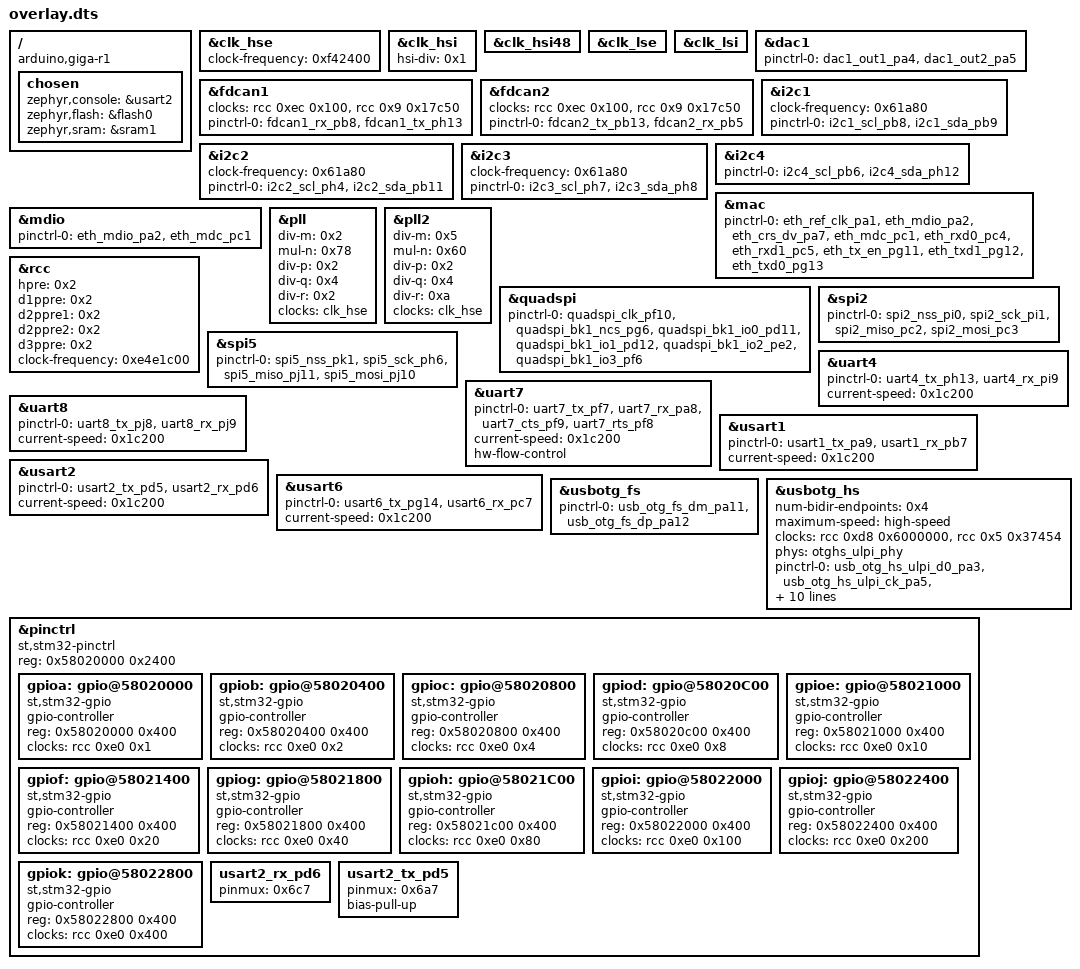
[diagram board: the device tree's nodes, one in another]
/ {
	compatible = "arduino,giga-r1";
	chosen {
		zephyr,console = &usart2;
		zephyr,flash = &flash0;
		zephyr,sram = &sram1;
	};
};
&clk_hse{
	status = "okay";
	clock-frequency = < 0xf42400 >;
};
&clk_hsi{
	status = "okay";
	hsi-div = < 0x1 >;
};
&clk_hsi48{
	status = "okay";
};
&clk_lse{
	status = "okay";
};
&clk_lsi{
	status = "okay";
};
&dac1{
	status = "okay";
	pinctrl-0 = < &dac1_out1_pa4 &dac1_out2_pa5 >;
	pinctrl-names = "default";
};
&fdcan1{
	clocks = < &rcc 0xec 0x100 >, < &rcc 0x9 0x17c50 >;
	pinctrl-0 = < &fdcan1_rx_pb8 &fdcan1_tx_ph13 >;
	pinctrl-names = "default";
};
&fdcan2{
	clocks = < &rcc 0xec 0x100 >, < &rcc 0x9 0x17c50 >;
	status = "okay";
	pinctrl-0 = < &fdcan2_tx_pb13 &fdcan2_rx_pb5 >;
	pinctrl-names = "default";
};
&i2c1{
	clock-frequency = < 0x61a80 >;
	pinctrl-0 = < &i2c1_scl_pb8 &i2c1_sda_pb9 >;
	pinctrl-names = "default";
};
&i2c2{
	clock-frequency = < 0x61a80 >;
	pinctrl-0 = < &i2c2_scl_ph4 &i2c2_sda_pb11 >;
	pinctrl-names = "default";
};
&i2c3{
	clock-frequency = < 0x61a80 >;
	pinctrl-0 = < &i2c3_scl_ph7 &i2c3_sda_ph8 >;
	pinctrl-names = "default";
};
&i2c4{
	status = "okay";
	pinctrl-0 = < &i2c4_scl_pb6 &i2c4_sda_ph12 >;
	pinctrl-names = "default";
};
&mac{
	pinctrl-0 = < &eth_ref_clk_pa1 &eth_mdio_pa2 &eth_crs_dv_pa7 &eth_mdc_pc1 &eth_rxd0_pc4 &eth_rxd1_pc5 &eth_tx_en_pg11 &eth_txd1_pg12 &eth_txd0_pg13 >;
	pinctrl-names = "default";
};
&mdio{
	status = "okay";
	pinctrl-0 = < &eth_mdio_pa2 &eth_mdc_pc1 >;
	pinctrl-names = "default";
};
&pll{
	status = "okay";
	div-m = < 0x2 >;
	mul-n = < 0x78 >;
	div-p = < 0x2 >;
	div-q = < 0x4 >;
	div-r = < 0x2 >;
	clocks = < &clk_hse >;
};
&pll2{
	status = "okay";
	div-m = < 0x5 >;
	mul-n = < 0x60 >;
	div-p = < 0x2 >;
	div-q = < 0x4 >;
	div-r = < 0xa >;
	clocks = < &clk_hse >;
};
&quadspi{
	status = "okay";
	pinctrl-0 = < &quadspi_clk_pf10 &quadspi_bk1_ncs_pg6 &quadspi_bk1_io0_pd11 &quadspi_bk1_io1_pd12 &quadspi_bk1_io2_pe2 &quadspi_bk1_io3_pf6 >;
	pinctrl-names = "default";
};
&rcc{
	hpre = < 0x2 >;
	d1ppre = < 0x2 >;
	d2ppre1 = < 0x2 >;
	d2ppre2 = < 0x2 >;
	d3ppre = < 0x2 >;
	clock-frequency = < 0xe4e1c00 >;
};
&spi2{
	pinctrl-0 = < &spi2_nss_pi0 &spi2_sck_pi1 &spi2_miso_pc2 &spi2_mosi_pc3 >;
	pinctrl-names = "default";
};
&spi5{
	status = "okay";
	pinctrl-0 = < &spi5_nss_pk1 &spi5_sck_ph6 &spi5_miso_pj11 &spi5_mosi_pj10 >;
	pinctrl-names = "default";
};
&uart4{
	pinctrl-0 = < &uart4_tx_ph13 &uart4_rx_pi9 >;
	pinctrl-names = "default";
	current-speed = < 0x1c200 >;
};
&uart7{
	status = "okay";
	pinctrl-0 = < &uart7_tx_pf7 &uart7_rx_pa8 &uart7_cts_pf9 &uart7_rts_pf8 >;
	pinctrl-names = "default";
	current-speed = < 0x1c200 >;
	hw-flow-control;
};
&uart8{
	pinctrl-0 = < &uart8_tx_pj8 &uart8_rx_pj9 >;
	pinctrl-names = "default";
	current-speed = < 0x1c200 >;
};
&usart1{
	status = "okay";
	pinctrl-0 = < &usart1_tx_pa9 &usart1_rx_pb7 >;
	pinctrl-names = "default";
	current-speed = < 0x1c200 >;
};
&usart2{
	status = "okay";
	pinctrl-0 = < &usart2_tx_pd5 &usart2_rx_pd6 >;
	pinctrl-names = "default";
	current-speed = < 0x1c200 >;
};
&usart6{
	pinctrl-0 = < &usart6_tx_pg14 &usart6_rx_pc7 >;
	pinctrl-names = "default";
	current-speed = < 0x1c200 >;
};
&usbotg_fs{
	status = "okay";
	pinctrl-0 = < &usb_otg_fs_dm_pa11 &usb_otg_fs_dp_pa12 >;
	pinctrl-names = "default";
};
&usbotg_hs{
	num-bidir-endpoints = < 0x4 >;
	maximum-speed = "high-speed";
	clocks = < &rcc 0xd8 0x6000000 >, < &rcc 0x5 0x37454 >;
	phys = < &otghs_ulpi_phy >;
	status = "okay";
	pinctrl-0 = < &usb_otg_hs_ulpi_d0_pa3 &usb_otg_hs_ulpi_ck_pa5 &usb_otg_hs_ulpi_d1_pb0 &usb_otg_hs_ulpi_d2_pb1 &usb_otg_hs_ulpi_d7_pb5 &usb_otg_hs_ulpi_d3_pb10 &usb_otg_hs_ulpi_d4_pb11 &usb_otg_hs_ulpi_d5_pb12 &usb_otg_hs_ulpi_d6_pb13 &usb_otg_hs_ulpi_stp_pc0 &usb_otg_hs_ulpi_nxt_ph4 &usb_otg_hs_ulpi_dir_pi11 >;
	pinctrl-names = "default";
};
&pinctrl{
	compatible = "st,stm32-pinctrl";
	#address-cells = < 0x1 >;
	#size-cells = < 0x1 >;
	reg = < 0x58020000 0x2400 >;
	gpioa: gpio@58020000 {
		compatible = "st,stm32-gpio";
		gpio-controller;
		#gpio-cells = < 0x2 >;
		reg = < 0x58020000 0x400 >;
		clocks = < &rcc 0xe0 0x1 >;
	};
	gpiob: gpio@58020400 {
		compatible = "st,stm32-gpio";
		gpio-controller;
		#gpio-cells = < 0x2 >;
		reg = < 0x58020400 0x400 >;
		clocks = < &rcc 0xe0 0x2 >;
	};
	gpioc: gpio@58020800 {
		compatible = "st,stm32-gpio";
		gpio-controller;
		#gpio-cells = < 0x2 >;
		reg = < 0x58020800 0x400 >;
		clocks = < &rcc 0xe0 0x4 >;
	};
	gpiod: gpio@58020C00 {
		compatible = "st,stm32-gpio";
		gpio-controller;
		#gpio-cells = < 0x2 >;
		reg = < 0x58020c00 0x400 >;
		clocks = < &rcc 0xe0 0x8 >;
	};
	gpioe: gpio@58021000 {
		compatible = "st,stm32-gpio";
		gpio-controller;
		#gpio-cells = < 0x2 >;
		reg = < 0x58021000 0x400 >;
		clocks = < &rcc 0xe0 0x10 >;
	};
	gpiof: gpio@58021400 {
		compatible = "st,stm32-gpio";
		gpio-controller;
		#gpio-cells = < 0x2 >;
		reg = < 0x58021400 0x400 >;
		clocks = < &rcc 0xe0 0x20 >;
	};
	gpiog: gpio@58021800 {
		compatible = "st,stm32-gpio";
		gpio-controller;
		#gpio-cells = < 0x2 >;
		reg = < 0x58021800 0x400 >;
		clocks = < &rcc 0xe0 0x40 >;
	};
	gpioh: gpio@58021C00 {
		compatible = "st,stm32-gpio";
		gpio-controller;
		#gpio-cells = < 0x2 >;
		reg = < 0x58021c00 0x400 >;
		clocks = < &rcc 0xe0 0x80 >;
	};
	gpioi: gpio@58022000 {
		compatible = "st,stm32-gpio";
		gpio-controller;
		#gpio-cells = < 0x2 >;
		reg = < 0x58022000 0x400 >;
		clocks = < &rcc 0xe0 0x100 >;
	};
	gpioj: gpio@58022400 {
		compatible = "st,stm32-gpio";
		gpio-controller;
		#gpio-cells = < 0x2 >;
		reg = < 0x58022400 0x400 >;
		clocks = < &rcc 0xe0 0x200 >;
	};
	gpiok: gpio@58022800 {
		compatible = "st,stm32-gpio";
		gpio-controller;
		#gpio-cells = < 0x2 >;
		reg = < 0x58022800 0x400 >;
		clocks = < &rcc 0xe0 0x400 >;
	};
	usart2_rx_pd6: usart2_rx_pd6 {
		pinmux = < 0x6c7 >;
	};
	usart2_tx_pd5: usart2_tx_pd5 {
		pinmux = < 0x6a7 >;
		bias-pull-up;
	};
};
